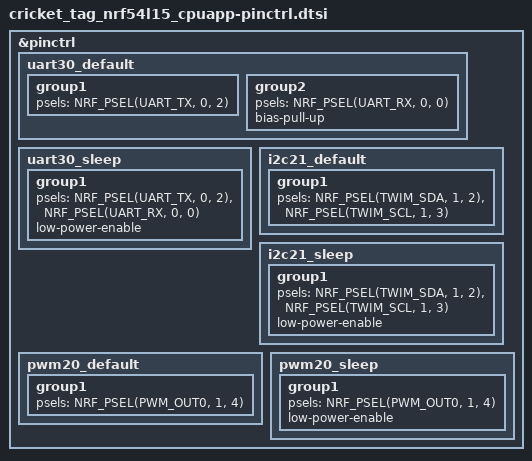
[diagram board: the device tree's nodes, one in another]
/*
 * SPDX-License-Identifier: MIT
 *
 * Pin map: hardware/cricket-tag/README.md (D-29).
 */

&pinctrl {
	/* MSP link to the flight controller through 1 kOhm resistors. RX is the inner pad 29. */
	uart30_default: uart30_default {
		group1 {
			psels = <NRF_PSEL(UART_TX, 0, 2)>;
		};

		group2 {
			psels = <NRF_PSEL(UART_RX, 0, 0)>;
			bias-pull-up;
		};
	};

	/* Without 5 V the FC is unpowered: keep TX disconnected so it does not feed the FC. */
	uart30_sleep: uart30_sleep {
		group1 {
			psels = <NRF_PSEL(UART_TX, 0, 2)>,
				<NRF_PSEL(UART_RX, 0, 0)>;
			low-power-enable;
		};
	};

	/* LIS2DH12. Former NFC pads; SCL must be on a clock pin. External 10 kOhm pull-ups. */
	i2c21_default: i2c21_default {
		group1 {
			psels = <NRF_PSEL(TWIM_SDA, 1, 2)>,
				<NRF_PSEL(TWIM_SCL, 1, 3)>;
		};
	};

	i2c21_sleep: i2c21_sleep {
		group1 {
			psels = <NRF_PSEL(TWIM_SDA, 1, 2)>,
				<NRF_PSEL(TWIM_SCL, 1, 3)>;
			low-power-enable;
		};
	};

	/* BUZ_DIN to PAM8904E */
	pwm20_default: pwm20_default {
		group1 {
			psels = <NRF_PSEL(PWM_OUT0, 1, 4)>;
		};
	};

	pwm20_sleep: pwm20_sleep {
		group1 {
			psels = <NRF_PSEL(PWM_OUT0, 1, 4)>;
			low-power-enable;
		};
	};
};
